# PIC18F04Q20 register map
Vendor: Microchip
Registers are 8-bit, read-write, reset 0x0 unless marked. A register's access mark holds for its fields unless they carry their own. Addresses are absolute, and some are shared; only a register's first bit layout is shown; [hi:lo] are bit positions; 'fields as' and 'values as' point back to an identical list.

## math_progcrc
0x60 CRCDATAL
  [7:0] DATA
0x61 CRCDATAH
  [7:0] DATA
0x62 CRCDATAU
  [7:0] DATA
0x63 CRCDATAT
  [7:0] DATA
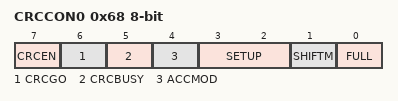
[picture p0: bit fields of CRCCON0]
0x68 CRCCON0
  [7] CRCEN, [6] CRCGO, [5] CRCBUSY ro, [4] ACCMOD, [3:2] SETUP, [1] SHIFTM, [0] FULL ro
0x69 CRCCON1
  [4:0] PLEN
0x6A CRCCON2
  [4:0] DLEN

## nvm_scan
0x6B SCANLADRL
  [7:0] LADR
0x6C SCANLADRH
  [7:0] LADR
0x6D SCANLADRU
  [5:0] LADR
0x6E SCANHADRL reset 0xFF
  [7:0] HADR
0x6F SCANHADRH reset 0xFF
  [7:0] HADR
0x70 SCANHADRU reset 0x3F
  [5:0] HADR
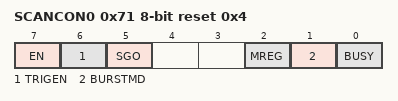
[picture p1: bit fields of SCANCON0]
0x71 SCANCON0 reset 0x4
  [7] EN, [6] TRIGEN, [5] SGO, [2] MREG, [1] BURSTMD, [0] BUSY
0x72 SCANTRIG
  [3:0] TSEL

## wdt_windowed
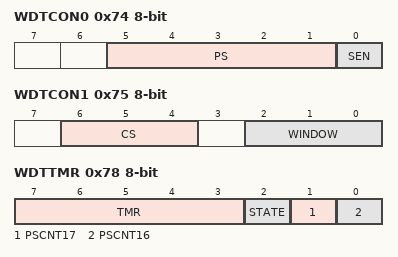
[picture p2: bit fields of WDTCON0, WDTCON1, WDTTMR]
0x74 WDTCON0 reset not defined — (power-on value --qqqqq0)
  [5:1] PS, [0] SEN
0x75 WDTCON1 reset not defined — (power-on value -qqq-qqq)
  [6:4] CS, [2:0] WINDOW
0x76 WDTPSL ro
  [7:0] PSCNTL
0x77 WDTPSH ro
  [7:0] PSCNTH
0x78 WDTTMR ro
  [7:3] TMR, [2] STATE, [1] PSCNT17, [0] PSCNT16

## clk_refout
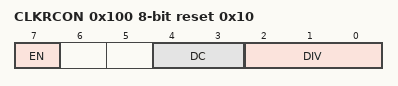
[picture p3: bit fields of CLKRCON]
0x100 CLKRCON reset 0x10
  [7] EN, [4:3] DC, [2:0] DIV
0x101 CLKRCLK
  [3:0] CLK

## tmr
0x103 TMR0L
0x104 TMR0H reset 0xFF
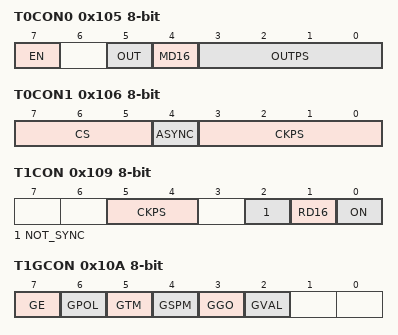
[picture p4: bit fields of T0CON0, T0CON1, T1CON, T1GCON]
0x105 T0CON0
  [7] EN, [5] OUT ro, [4] MD16, [3:0] OUTPS
0x106 T0CON1
  [7:5] CS, [4] ASYNC, [3:0] CKPS
0x107 TMR1L
0x108 TMR1H
0x109 T1CON
  [5:4] CKPS, [2] NOT_SYNC, [1] RD16, [0] ON
0x10A T1GCON reset not defined — (power-on value 00000x--)
  [7] GE, [6] GPOL, [5] GTM, [4] GSPM, [3] GGO, [2] GVAL ro
0x10B T1GATE
  [3:0] GSS
0x10C T1CLK
  [3:0] CS
0x119 T2TMR — 8-bit period timer
  [7:0] TMR2
0x11A T2PR reset 0xFF
  [7:0] PR2
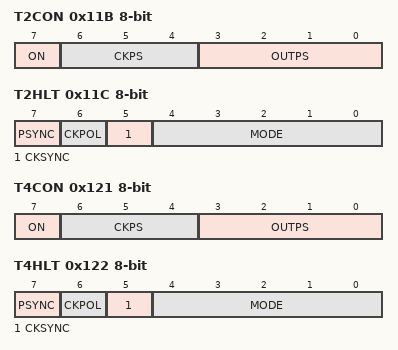
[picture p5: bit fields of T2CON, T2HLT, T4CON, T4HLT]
0x11B T2CON
  [7] ON, [6:4] CKPS, [3:0] OUTPS
0x11C T2HLT
  [7] PSYNC, [6] CKPOL, [5] CKSYNC, [4:0] MODE
0x11D T2CLKCON
  [3:0] CS
0x11E T2RST
  [4:0] RSEL
0x11F T4TMR — 8-bit period timer
  [7:0] TMR4
0x120 T4PR reset 0xFF
  [7:0] PR4
0x121 T4CON
  [7] ON, [6:4] CKPS, [3:0] OUTPS
0x122 T4HLT
  [7] PSYNC, [6] CKPOL, [5] CKSYNC, [4:0] MODE
0x123 T4CLKCON
  [2:0] CS
0x124 T4RST
  [3:0] RSEL
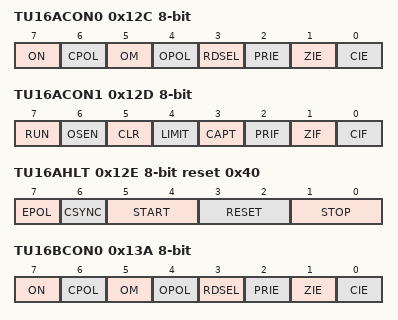
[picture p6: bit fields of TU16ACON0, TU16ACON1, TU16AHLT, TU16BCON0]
0x12C TU16ACON0
  [7] ON, [6] CPOL, [5] OM, [4] OPOL, [3] RDSEL, [2] PRIE, [1] ZIE, [0] CIE
0x12D TU16ACON1
  [7] RUN ro, [6] OSEN, [5] CLR, [4] LIMIT, [3] CAPT, [2] PRIF, [1] ZIF, [0] CIF
0x12E TU16AHLT reset 0x40
  [7] EPOL, [6] CSYNC, [5:4] START, [3:2] RESET, [1:0] STOP
0x12F TU16APS
  [7:0] PS
0x134 TU16APRL reset 0xFF
  [7:0] PRL
0x135 TU16APRH reset 0xFF
  [7:0] PRH
0x137 TU16APRT reset 0xFF
  [7:0] PRT
0x138 TU16ACLK
  [4:0] CLK
0x139 TU16AERS
  [5:0] ERS
0x13A TU16BCON0
  fields as TU16ACON0
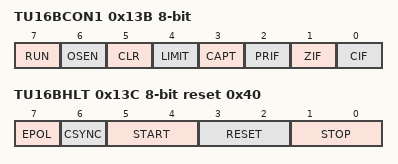
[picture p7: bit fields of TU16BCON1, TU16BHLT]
0x13B TU16BCON1
  fields as TU16ACON1
0x13C TU16BHLT reset 0x40
  [7] EPOL, [6] CSYNC, [5:4] START, [3:2] RESET, [1:0] STOP
0x13D TU16BPS
  [7:0] PS
0x142 TU16BPRL reset 0xFF
  [7:0] PRL
0x143 TU16BPRH reset 0xFF
  [7:0] PRH
0x145 TU16BPRT reset 0xFF
  [7:0] PRT
0x146 TU16BCLK
  [4:0] CLK
0x147 TU16BERS
  [5:0] ERS

## ccp
0x149 CCPR1L reset not defined — (power-on value xxxxxxxx)
  [7:0] RL
0x14A CCPR1H reset not defined — (power-on value xxxxxxxx)
  [7:0] RH
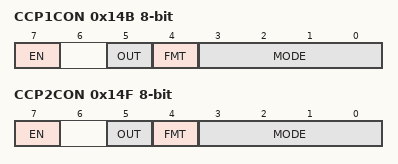
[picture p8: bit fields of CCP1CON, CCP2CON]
0x14B CCP1CON
  [7] EN, [5] OUT ro, [4] FMT, [3:0] MODE
0x14C CCP1CAP
  [2:0] CTS
0x14D CCPR2L reset not defined — (power-on value xxxxxxxx)
  [7:0] RL
0x14E CCPR2H reset not defined — (power-on value xxxxxxxx)
  [7:0] RH
0x14F CCP2CON
  [7] EN, [5] OUT ro, [4] FMT, [3:0] MODE
0x150 CCP2CAP
  [2:0] CTS

## pwm_cmp
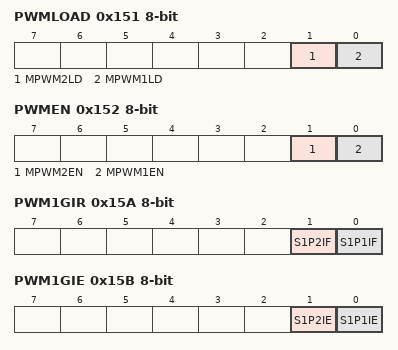
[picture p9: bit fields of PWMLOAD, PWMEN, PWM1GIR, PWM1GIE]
0x151 PWMLOAD
  [1] MPWM2LD, [0] MPWM1LD
0x152 PWMEN
  [1] MPWM2EN, [0] MPWM1EN
0x153 PWM1ERS
  [3:0] ERS
0x154 PWM1CLK
  [3:0] CLK
0x155 PWM1LDS
  [3:0] LDS
0x156 PWM1PRL
  [7:0] PRL
0x157 PWM1PRH
  [7:0] PRH
0x158 PWM1CPRE
  [7:0] CPRE
0x159 PWM1PIPOS
  [7:0] PIPOS
0x15A PWM1GIR
  [1] S1P2IF, [0] S1P1IF
0x15B PWM1GIE
  [1] S1P2IE, [0] S1P1IE
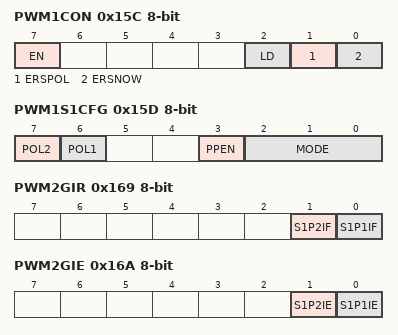
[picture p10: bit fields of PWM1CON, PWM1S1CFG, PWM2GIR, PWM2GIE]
0x15C PWM1CON
  [7] EN, [2] LD, [1] ERSPOL, [0] ERSNOW
0x15D PWM1S1CFG
  [7] POL2, [6] POL1, [3] PPEN, [2:0] MODE
0x15E PWM1S1P1L
  [7:0] S1P1L
0x15F PWM1S1P1H
  [7:0] S1P1H
0x160 PWM1S1P2L
  [7:0] S1P2L
0x161 PWM1S1P2H
  [7:0] S1P2H
0x162 PWM2ERS
  [3:0] ERS
0x163 PWM2CLK
  [3:0] CLK
0x164 PWM2LDS
  [3:0] LDS
0x165 PWM2PRL
  [7:0] PRL
0x166 PWM2PRH
  [7:0] PRH
0x167 PWM2CPRE
  [7:0] CPRE
0x168 PWM2PIPOS
  [7:0] PIPOS
0x169 PWM2GIR
  [1] S1P2IF, [0] S1P1IF
0x16A PWM2GIE
  [1] S1P2IE, [0] S1P1IE
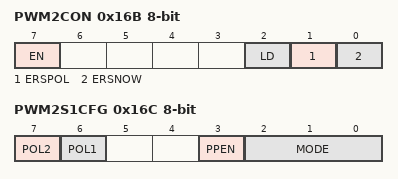
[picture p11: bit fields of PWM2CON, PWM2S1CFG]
0x16B PWM2CON
  [7] EN, [2] LD, [1] ERSPOL, [0] ERSNOW
0x16C PWM2S1CFG
  [7] POL2, [6] POL1, [3] PPEN, [2:0] MODE
0x16D PWM2S1P1L
  [7:0] S1P1L
0x16E PWM2S1P1H
  [7:0] S1P1H
0x16F PWM2S1P2L
  [7:0] S1P2L
0x170 PWM2S1P2H
  [7:0] S1P2H
